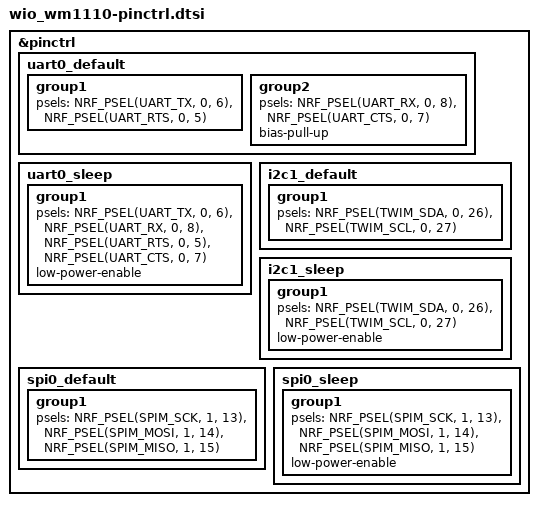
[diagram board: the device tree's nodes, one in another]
/*
 * Copyright (c) 2022 Nordic Semiconductor
 * SPDX-License-Identifier: Apache-2.0
 */

&pinctrl {

	uart0_default: uart0_default {
		group1 {
			psels = <NRF_PSEL(UART_TX, 0, 6)>,
				<NRF_PSEL(UART_RTS, 0, 5)>;
		};
		group2 {
			psels = <NRF_PSEL(UART_RX, 0, 8)>,
				<NRF_PSEL(UART_CTS, 0, 7)>;
			bias-pull-up;
		};
	};

	uart0_sleep: uart0_sleep {
		group1 {
			psels = <NRF_PSEL(UART_TX, 0, 6)>,
				<NRF_PSEL(UART_RX, 0, 8)>,
				<NRF_PSEL(UART_RTS, 0, 5)>,
				<NRF_PSEL(UART_CTS, 0, 7)>;
			low-power-enable;
		};
	};

	i2c1_default: i2c1_default {
		group1 {
			psels = <NRF_PSEL(TWIM_SDA, 0, 26)>,
				<NRF_PSEL(TWIM_SCL, 0, 27)>;
		};
	};

	i2c1_sleep: i2c1_sleep {
		group1 {
			psels = <NRF_PSEL(TWIM_SDA, 0, 26)>,
				<NRF_PSEL(TWIM_SCL, 0, 27)>;
			low-power-enable;
		};
	};

	spi0_default: spi0_default {
		group1 {
			psels = <NRF_PSEL(SPIM_SCK,  1, 13)>,
				<NRF_PSEL(SPIM_MOSI, 1, 14)>,
				<NRF_PSEL(SPIM_MISO, 1, 15)>;
		};
	};

	spi0_sleep: spi0_sleep {
		group1 {
			psels = <NRF_PSEL(SPIM_SCK,  1, 13)>,
				<NRF_PSEL(SPIM_MOSI, 1, 14)>,
				<NRF_PSEL(SPIM_MISO, 1, 15)>;
			low-power-enable;
		};
	};
};
